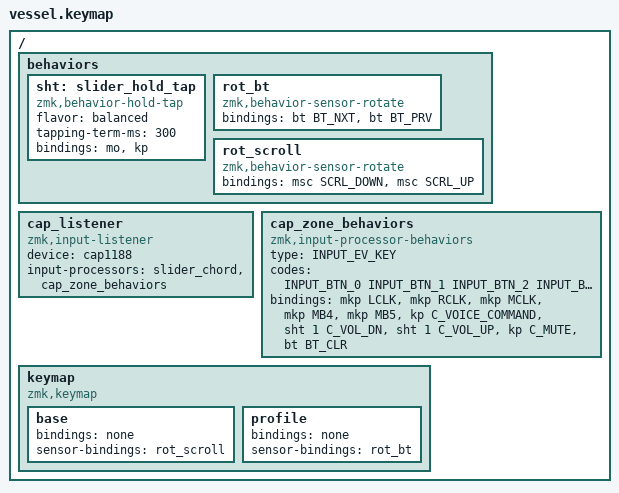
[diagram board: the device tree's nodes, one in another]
#include <behaviors.dtsi>
#include <dt-bindings/zmk/keys.h>
#include <dt-bindings/zmk/pointing.h>   /* &mkp, LCLK/RCLK/MCLK */
#include <dt-bindings/zmk/bt.h>
#include <zephyr/dt-bindings/input/input-event-codes.h>   /* INPUT_EV_KEY, INPUT_BTN_* */

/ {
    /* Work item 8: profile-switch gesture pieces.
     * - sht: hold-tap on the slider pads. Quick tap = volume step (item 4);
     *   holding ~300 ms = momentary "profile" layer, where the crown spins
     *   through BLE profiles instead of volume.
     * - rot_bt: crown rotation -> next/previous BLE profile. Feedback (haptic
     *   tick + LED index blink) comes from the module's profile listener.
     * ZMK ships 5 BLE profiles by default = the spec's 5. */
    behaviors {
        sht: slider_hold_tap {
            compatible = "zmk,behavior-hold-tap";
            #binding-cells = <2>;
            flavor = "balanced";
            tapping-term-ms = <300>;
            bindings = <&mo>, <&kp>;
        };
        rot_bt: rot_bt {
            compatible = "zmk,behavior-sensor-rotate";
            #sensor-binding-cells = <0>;
            bindings = <&bt BT_NXT>, <&bt BT_PRV>;
        };
        /* Item 9: crown = true wheel scroll. One wheel tick per detent
         * (24/rev). If direction is inverted on the bench, swap SCRL_DOWN/
         * SCRL_UP here (or swap a-gpios/b-gpios in the overlay — one fix,
         * not both). */
        rot_scroll: rot_scroll {
            compatible = "zmk,behavior-sensor-rotate";
            #sensor-binding-cells = <0>;
            bindings = <&msc SCRL_DOWN>, <&msc SCRL_UP>;
        };
    };

    /* Work items 2+3: CAP1188 touch -> ZMK behaviors.
     * The CAP1188 (vessel.overlay, on &i2c1) emits one INPUT_EV_KEY event per
     * channel. This listener runs those events through a behaviors processor
     * that invokes one ZMK behavior per channel code. This is the spec §4.2
     * PRIMARY path (stock driver + listener shim) — no custom module.
     *
     * Zone map (spec §3): CS1 L-click, CS2 R-click, CS3 M-click, CS4 back,
     * CS5 forward, CS6 PTT-as-dictation-hotkey-hold. The processor presses a
     * binding on touch and releases it on lift, so CS6 holds the dictation key
     * for as long as the finger stays on the zone — PTT semantics for free.
     * CS7/CS8 (slider — item 4) stay &none until that PR. */
    cap_listener: cap_listener {
        compatible = "zmk,input-listener";
        device = <&cap1188>;
        /* Order matters: the chord processor (vessel.overlay) rewrites the
         * CS7/CS8 stream first; the behaviors map then sees either the
         * individual codes or the synthesized KEY_MUTE. */
        input-processors = <&slider_chord>, <&cap_zone_behaviors>;
    };

    cap_zone_behaviors: cap_zone_behaviors {
        compatible = "zmk,input-processor-behaviors";
        #input-processor-cells = <0>;
        type = <INPUT_EV_KEY>;
        codes = <INPUT_BTN_0 INPUT_BTN_1 INPUT_BTN_2 INPUT_BTN_3
                 INPUT_BTN_4 INPUT_BTN_5 INPUT_BTN_6 INPUT_BTN_7
                 INPUT_KEY_MUTE INPUT_KEY_BLUETOOTH>;
        /* CS1->L, CS2->R, CS3->M click; CS4->back, CS5->forward (browser
         * back/fwd = mouse buttons 4/5). CS6 holds C_VOICE_COMMAND (HID
         * consumer 0xCF, the mic/dictation key on modern keyboards): macOS
         * maps it to dictation, Windows 11 to voice typing, iOS/Android to
         * the assistant. TUNING POINT: if the host doesn't honor 0xCF, swap
         * for its dictation chord instead — e.g. &kp LG(H) (Win+H) on
         * Windows 10 — see HARDWARE_VALIDATION.md §4.
         *
         * Slider v1 (item 4) + item 8: CS7/CS8 are hold-taps — tap = volume
         * step (item 9 confirms the slider owns volume), hold = the profile
         * layer for crown switching. KEY_MUTE and KEY_BLUETOOTH never come
         * from the chip: &slider_chord synthesizes MUTE on a two-pad chord
         * and BLUETOOTH on a lone-pad 5 s long-hold (-> &bt BT_CLR, the
         * spec's "long-hold = BT_CLR"). */
        bindings = <&mkp LCLK>, <&mkp RCLK>, <&mkp MCLK>,
                   <&mkp MB4>, <&mkp MB5>, <&kp C_VOICE_COMMAND>,
                   <&sht 1 C_VOL_DN>, <&sht 1 C_VOL_UP>,
                   <&kp C_MUTE>, <&bt BT_CLR>;
    };

    keymap {
        compatible = "zmk,keymap";

        base {
            /* v1 work item 1: the D0/D1 mouse-click buttons are gone (D0/D1 are
             * the CAP1188 ALERT/RESET now). The kscan is a 1x1 mock placeholder,
             * so this layer has a single &none. Real click/zone behaviors arrive
             * in PR-2/PR-3 driven by the CAP1188 input listener, not this keymap. */
            bindings = <
                &none
            >;

            /* Item 9: the crown is a real scroll wheel now; volume belongs
             * to the slider (CS7/CS8, item 4). Spin toward you = scroll
             * down, the mouse-wheel convention. */
            sensor-bindings = <&rot_scroll>;
        };

        profile {
            /* Item 8: active while a slider pad is held (&sht). The crown
             * steps BLE profiles; everything else keeps its base behavior
             * (zone bindings live in the input processor, not this layer). */
            bindings = <
                &none
            >;
            sensor-bindings = <&rot_bt>;
        };
    };
};
